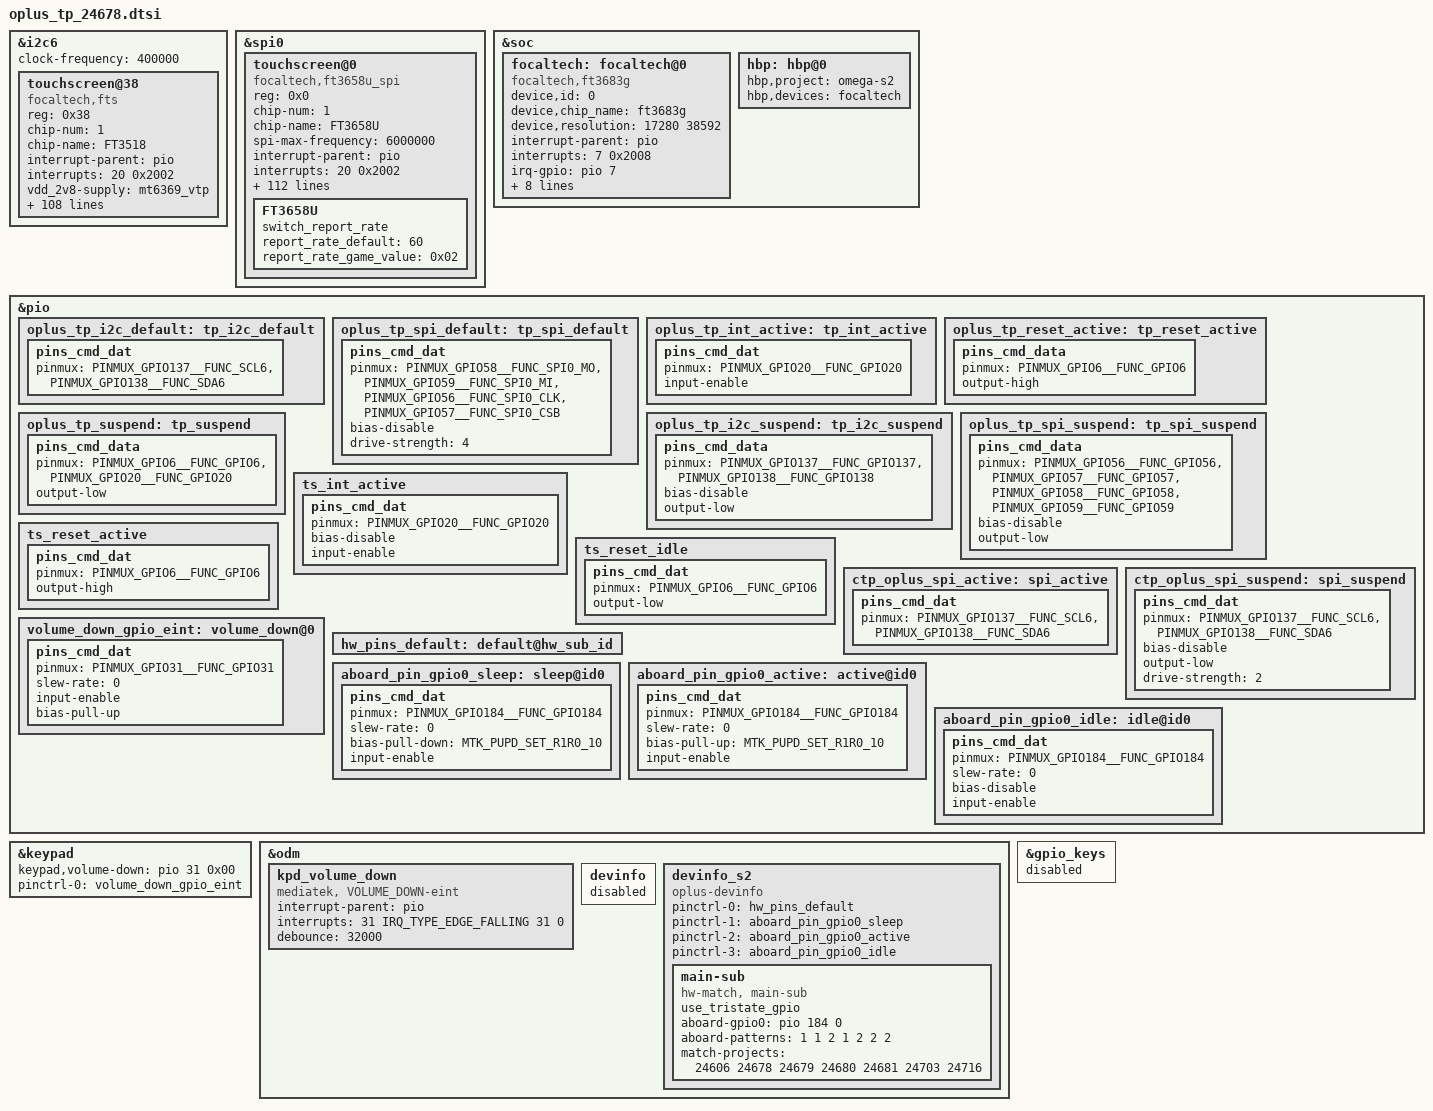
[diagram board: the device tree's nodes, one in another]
&i2c6 {
	status = "okay";
	#address-cells = <1>;
	#size-cells = <0>;
        clock-frequency = <400000>;
	touchscreen@38{
	    status = "okay";
		compatible = "focaltech,fts";
		reg = <0x38>;
		chip-num = <1>;
		chip-name = "FT3518";

		//spi-max-frequency = <12000000>;
		/* Interrupt && Irq-gpio */
		interrupt-parent = <&pio>;
		interrupts = <20 0x2002>;

		/* Power Config */
		vdd_2v8-supply  = <&mt6369_vtp>;
		vdd_2v8_volt = <3000000>;
		enable1v8_gpio = <&pio 22 0x1>;
		//vcc_1v8-supply  = <&mt6369_vtp>;
		//vcc_1v8_volt = <1800000>;


		/* Other HW Resource */

		irq-gpio = <&pio 20 0x2002>;
		reset-gpio = <&pio 6 0x1>;
		i2c_spi_switch = <&pio 41 0x1>;

		pinctrl-names = "default",  "sleep";
		pinctrl-0 = <&oplus_tp_int_active &oplus_tp_reset_active &oplus_tp_i2c_default>;
		pinctrl-1 = <&oplus_tp_suspend &oplus_tp_i2c_suspend>;

		touchpanel,max-num-support = <10>;
		touchpanel,tx-rx-num = <16 34>;
		touchpanel,panel-coords = <8640 19200>;
		touchpanel,display-coords = <1080 2400>;
		touchpanel,touchmajor-limit = <0 54>;
		touchpanel,smooth-level = <255 15 40 80 160 240>;
		touchpanel,sensitive-level = <255 30 25 20 10 8>;
		touchpanel,high-frame-rate-time = <20>;
		touchpanel,single-optimized-time = <8>;

		panel_type = <8>;
		firmware_name = "A865FT1";
		platform_support_project = <24606 24678 24679 24680 24681 24703 24716>;
		platform_support_project_dir = <24679 24679 24679 24679 24679 24679 24679>;
		platform_support_project_commandline = "default_commandline","default_commandline";

		prevention,curved_screen_V2;
		prevention,grip_disable_level = <6>;
		prevention,updelay_time_ms = <30>;
		prevention,makeup_cnt_weight = <4 1 2 2 2>;
		prevention,large_corner_range = <960 2400>;
		prevention,large_corner_judge_condition = <500 300 800 7 7>;
		prevention,trx_reject_condition = <9 6 7>;
		prevention,trx_strict_reject_condition = <8 5 6>;
		prevention,large_judge_time_ms = <500 50 30>;
		prevention,large_exit_condition = <8 8 2>;
		prevention,single_channel_width = <160 160>;
		prevention,normal_tap_condition = <10 350>;
		prevention,long_edge_condition = <200 80 180 80>;
		prevention,long_strict_edge_condition = <160 60>;
		prevention,long_fingerhold_condition = <50 6 4 4>;
		prevention,short_edge_condition = <200 80 180 80>;
		prevention,short_strict_edge_condition = <160 60>;
		prevention,large_strict_exit_condition = <4 4>;
		prevention,top_corner_config = <440 1200 360>;
		prevention,edge_swipe_config = <240 960>;

		prevention,curved_screen_V4;
		prevention,long_eliminate_point_type = <2 8640 6400 240 19200 300 1>;
		prevention,long_fingerhold_condition2 = <420 0 0 0>;
		prevention,top_corner_config2 = <3 80 480 0 0>;
		prevention,hor_long_top_corner_config = <240 1600 0 0>;
		prevention,top_middle_config = <8640 800 800 0>;
		prevention,corner_eliminate_point_type = <0 960 1600 1>;
		prevention,finger_hold_differ_size = <1 0 240 300>;
		prevention,finger_hold_max_rx_exit_distance = <5 240 1600>;
		prevention,max_rx_exit_distance = <1 5 150 240 1600>;
		prevention,dynamic_finger_hold_exit_distance = <1 240 1600 360>;
		prevention,edge_sliding_matched_support = <1 150 3 0>;
		//grip v4.2 reclining mode
		prevention,reclining_mode_support = <1>;
		prevention,long_eliminate_point_type_recli = <2 8640 6400 240 19200 500 0>;
		prevention,finger_hold_differ_size_recli = <1 0 240 400>;
		prevention,finger_hold_max_rx_exit_distance_recli = <4 240 1600>;
		prevention,max_rx_exit_distance_recli = <1 4 100 240 1600>;
		prevention,dynamic_finger_hold_exit_distance_recli = <1 240 1600 360>;
		prevention,edge_sliding_matched_support_recli = <1 200 3 0>;
		prevention,long_edge_condition_recli = <160 80 120 80>;

		/* SW Support Feature Control */
		black_gesture_support;
		black_gesture_indep_support;
		sportify_aod_gesture_support;
		pressure_report_support;
		charger_pump_support;
		game_switch_support;
		smart_gesture_support;
		fw_update_app_support;
		fingerprint_underscreen_support;
		screenoff_fingerprint_info_support;
		irq_need_dev_resume_ok;
		kernel_grip_support;
		//fw_edge_limit_support;
		exception_upload_support;
		health_monitor_support;
		//focalt x8 resolution config
		high_resolution_support;
		high_resolution_support_x8;
		disable_suspend_irq_handler_support;
		palm_to_sleep_support;
		snr_read_support;
		i2c_spi_compatible_support;
		esd_handle_support;
		diaphragm_touch_support;
		report_rate_white_list_support;
		/*
			*Virtual Key Config:
			*1:touchpanel,button-type: <virtualkey_type  supportted_button-map>
			*virtualkey_type:
			*Type 1: using board_properties
			*Type 2: using same IC (button zone&& touch zone are seprate)
			*Type 3: using diffrent IC (button zone&& touch zone are seprate)
			*Type 4: No need of virtual key process
			*supportted_button-map:select|menu|home|back
			*
			*2:touchpanel,button-map
			*type (X1,Y1)(X2,Y2)(X3,Y3)(Width_X,Hight_Y)--Only when button-type is 0
		*/
		touchpanel,button-type = <4>;
		touchpanel.button-TRx = <0 0>;

	};
};
&spi0 {
	status = "okay";
	#address-cells = <1>;
	#size-cells = <0>;
	touchscreen@0{
		compatible = "focaltech,ft3658u_spi";
		reg = <0x0>;
		chip-num = <1>;
		chip-name = "FT3658U";
		status = "okay";
		spi-max-frequency = <6000000>;
		/* Interrupt && Irq-gpio */
		interrupt-parent = <&pio>;
		interrupts = <20 0x2002>;

		/* Power Config */
		vdd_2v8-supply  = <&mt6369_vtp>;
		vdd_2v8_volt = <3000000>;
		enable1v8_gpio = <&pio 22 0x1>;
		//vcc_1v8-supply  = <&mt6369_vtp>;
		//vcc_1v8_volt = <1800000>;


		/* Other HW Resource */

		irq-gpio = <&pio 20 0x2002>;
		reset-gpio = <&pio 6 0x1>;
		i2c_spi_switch = <&pio 41 0x1>;

		pinctrl-names = "default",  "sleep";
		pinctrl-0 = <&oplus_tp_int_active &oplus_tp_reset_active &oplus_tp_spi_default>;
		pinctrl-1 = <&oplus_tp_suspend &oplus_tp_spi_suspend>;

		project_id = <24679>;
		touchpanel,max-num-support = <10>;
		touchpanel,tx-rx-num = <16 34>;
		touchpanel,panel-coords = <8640 19200>;
		touchpanel,display-coords = <1080 2400>;
		touchpanel,touchmajor-limit = <0 54>;
		touchpanel,smooth-level = <255 15 40 80 160 240>;
		touchpanel,sensitive-level = <255 30 25 20 10 8>;
		touchpanel,high-frame-rate-time = <20>;
		touchpanel,single-optimized-time = <8>;

		tp_type = <8 8>;
		firmware_name = "A865FT2";
		panel_type = <8>;
		platform_support_project = <24606 24678 24679 24680 24681 24703 24716>;
		platform_support_project_dir = <24679 24679 24679 24679 24679 24716 24716>;
		platform_support_project_commandline = "s6e8fc3_fhdp_dsi_vdo_samsung_ams667fk03_lcm_drv";

		prevention,curved_screen_V2;
		prevention,grip_disable_level = <6>;
		prevention,updelay_time_ms = <30>;
		prevention,makeup_cnt_weight = <4 1 2 2 2>;
		prevention,large_corner_range = <960 2400>;
		prevention,large_corner_judge_condition = <500 300 800 7 7>;
		prevention,trx_reject_condition = <9 6 7>;
		prevention,trx_strict_reject_condition = <8 5 6>;
		prevention,large_judge_time_ms = <500 50 30>;
		prevention,large_exit_condition = <8 8 2>;
		prevention,single_channel_width = <160 160>;
		prevention,normal_tap_condition = <10 350>;
		prevention,long_edge_condition = <200 80 180 80>;
		prevention,long_strict_edge_condition = <160 60>;
		prevention,long_fingerhold_condition = <50 6 4 4>;
		prevention,short_edge_condition = <200 80 180 80>;
		prevention,short_strict_edge_condition = <160 60>;
		prevention,large_strict_exit_condition = <4 4>;
		prevention,top_corner_config = <440 1200 360>;
		prevention,edge_swipe_config = <240 960>;

		prevention,curved_screen_V4;
		prevention,long_eliminate_point_type = <2 8640 6400 240 19200 300 1>;
		prevention,long_fingerhold_condition2 = <420 0 0 0>;
		prevention,top_corner_config2 = <3 80 480 0 0>;
		prevention,hor_long_top_corner_config = <240 1600 0 0>;
		prevention,top_middle_config = <8640 800 800 0>;
		prevention,corner_eliminate_point_type = <0 960 1600 1>;
		prevention,finger_hold_differ_size = <1 0 240 300>;
		prevention,finger_hold_max_rx_exit_distance = <5 240 1600>;
		prevention,max_rx_exit_distance = <1 5 150 240 1600>;
		prevention,dynamic_finger_hold_exit_distance = <1 240 1600 360>;
		prevention,edge_sliding_matched_support = <1 150 3 0>;
		//grip v4.2 reclining mode
		prevention,reclining_mode_support = <1>;
		prevention,long_eliminate_point_type_recli = <2 8640 6400 240 19200 500 0>;
		prevention,finger_hold_differ_size_recli = <1 0 240 400>;
		prevention,finger_hold_max_rx_exit_distance_recli = <4 240 1600>;
		prevention,max_rx_exit_distance_recli = <1 4 100 240 1600>;
		prevention,dynamic_finger_hold_exit_distance_recli = <1 240 1600 360>;
		prevention,edge_sliding_matched_support_recli = <1 200 3 0>;
		prevention,long_edge_condition_recli = <160 80 120 80>;

		/* SW Support Feature Control */
		black_gesture_support;
		black_gesture_indep_support;
		sportify_aod_gesture_support;
		pressure_report_support;
		charger_pump_support;
		game_switch_support;
		smart_gesture_support;
		fw_update_app_support;
		fingerprint_underscreen_support;
		screenoff_fingerprint_info_support;
		irq_need_dev_resume_ok;
		kernel_grip_support;
		//fw_edge_limit_support;
		exception_upload_support;
		health_monitor_support;
		//focalt x8 resolution config
		high_resolution_support;
		high_resolution_support_x8;
		disable_suspend_irq_handler_support;
		palm_to_sleep_support;
		snr_read_support;
		auto_test_force_pass_support;
		i2c_spi_compatible_support;
		esd_handle_support;
		diaphragm_touch_support;
		report_rate_white_list_support;
		/*
		*Virtual Key Config:
		*1:touchpanel,button-type: <virtualkey_type  supportted_button-map>
		*virtualkey_type:
		*Type 1: using board_properties
		*Type 2: using same IC (button zone&& touch zone are seprate)
		*Type 3: using diffrent IC (button zone&& touch zone are seprate)
		*Type 4: No need of virtual key process
		*supportted_button-map:select|menu|home|back
		*
		*2:touchpanel,button-map
		*type (X1,Y1)(X2,Y2)(X3,Y3)(Width_X,Hight_Y)--Only when button-type is 0
		*/
		touchpanel,button-type = <4>;
		touchpanel.button-TRx = <0 0>;

		FT3658U {
			switch_report_rate;
			report_rate_default = <60>;
			report_rate_game_value = <0x02>;
		};
	};
};
&soc {
	focaltech:focaltech@0 {
		compatible = "focaltech,ft3683g";
		status = "okay";

		device,id = <0>;
		device,chip_name = "ft3683g";
		device,resolution = <17280 38592>;

		/*interrupt config*/
		interrupt-parent = <&pio>;
		interrupts = <7 0x2008>;
		irq-gpio = <&pio 7 0x2002>;

		pinctrl-names = "default",
			"ts_reset_active",
			"ts_reset_idle",
			"ts_resume",
			"ts_suspend";
		pinctrl-0 = <&ts_int_active &ts_reset_active>;
		pinctrl-1 = <&ts_reset_active>;
		pinctrl-2 = <&ts_reset_idle>;
		pinctrl-3 = <&ctp_oplus_spi_active>;
		pinctrl-4 = <&ctp_oplus_spi_suspend>;

		/*cs active state, not used now*/
		spi,cs_active = <0>;

		/*power config*/
		// power,avdd-supply = <&wl28681c1_ldo6a>;
		// power,avdd_volt = <3204000 3204000>;
		power,vddi-supply = <&mt6369_vtp>;
		power,vddi_volt = <1800000 1800000>;

	};

	hbp:hbp@0 {
		//compatible = "oplus,hbp_core";
		hbp,project = "omega-s2";
		hbp,devices = <&focaltech>;
	};
};

&pio {
    oplus_tp_i2c_default: tp_i2c_default {
		pins_cmd_dat {
			pinmux =<PINMUX_GPIO137__FUNC_SCL6>,
					<PINMUX_GPIO138__FUNC_SDA6>;
		};
	};

    oplus_tp_spi_default: tp_spi_default {
		pins_cmd_dat {
		pinmux = <PINMUX_GPIO58__FUNC_SPI0_MO>,
				<PINMUX_GPIO59__FUNC_SPI0_MI>,
				<PINMUX_GPIO56__FUNC_SPI0_CLK>,
				<PINMUX_GPIO57__FUNC_SPI0_CSB>;
			bias-disable;
			drive-strength = <4>;
		};
	};

	oplus_tp_int_active: tp_int_active {
		pins_cmd_dat {
			pinmux = <PINMUX_GPIO20__FUNC_GPIO20>;
			input-enable;
		};
	};
	oplus_tp_reset_active: tp_reset_active {
		pins_cmd_data {
			pinmux = <PINMUX_GPIO6__FUNC_GPIO6>;
			output-high;
		};
	};
	oplus_tp_suspend: tp_suspend {
		pins_cmd_data {
			pinmux = <PINMUX_GPIO6__FUNC_GPIO6>,
					<PINMUX_GPIO20__FUNC_GPIO20>;
			output-low;
		};
	};

    oplus_tp_i2c_suspend: tp_i2c_suspend {
		pins_cmd_data {
			pinmux = <PINMUX_GPIO137__FUNC_GPIO137>,
			         <PINMUX_GPIO138__FUNC_GPIO138>;
			bias-disable;
			output-low;
		};
	};

	oplus_tp_spi_suspend: tp_spi_suspend {
		pins_cmd_data {
			pinmux = <PINMUX_GPIO56__FUNC_GPIO56>,
					<PINMUX_GPIO57__FUNC_GPIO57>,
					<PINMUX_GPIO58__FUNC_GPIO58>,
					<PINMUX_GPIO59__FUNC_GPIO59>;
			bias-disable;
			output-low;
		};
	};

	/*add for omega TP*/
	ts_int_active: ts_int_active {
		pins_cmd_dat {
			pinmux = <PINMUX_GPIO20__FUNC_GPIO20>;
			bias-disable;
			input-enable;
		};
	};
	ts_reset_active: ts_reset_active {
		pins_cmd_dat {
			pinmux = <PINMUX_GPIO6__FUNC_GPIO6>;
			output-high;
		};
	};
	ts_reset_idle: ts_reset_idle {
		pins_cmd_dat {
			pinmux = <PINMUX_GPIO6__FUNC_GPIO6>;
			output-low;
		};
	};
	ctp_oplus_spi_active: spi_active {
		pins_cmd_dat {
			pinmux = <PINMUX_GPIO137__FUNC_SCL6>,
					<PINMUX_GPIO138__FUNC_SDA6>;
		};
	};
	ctp_oplus_spi_suspend: spi_suspend {
		pins_cmd_dat {
			pinmux = <PINMUX_GPIO137__FUNC_SCL6>,
                     <PINMUX_GPIO138__FUNC_SDA6>;
			bias-disable;
			output-low;
			drive-strength = <2>;
		};
	};

};

&keypad {
		keypad,volume-down = <&pio 31 0x00>;
		pinctrl-names = "volume_down_as_int";
		pinctrl-0 = <&volume_down_gpio_eint>;
		status = "okay";
};

&pio {
        volume_down_gpio_eint:volume_down@0{
                pins_cmd_dat {
                        pinmux = <PINMUX_GPIO31__FUNC_GPIO31>;
                        slew-rate = <0>;  /*direction 0:in, 1:out*/
                        input-enable;
                        bias-pull-up;
                };
        };
};

&odm {
        kpd_volume_down:kpd_volume_down {
                compatible = "mediatek, VOLUME_DOWN-eint";
                interrupt-parent = <&pio>;
                interrupts = <31 IRQ_TYPE_EDGE_FALLING 31 0>;
                debounce = <32000>;
                status = "okay";
        };
};

&odm {
	devinfo {
		status = "disabled";
	};

	devinfo_s2 {
		compatible = "oplus-devinfo";

		pinctrl-names = "default", "aboard_gpio0_sleep", "aboard_gpio0_active", "aboard_gpio0_idle";
		pinctrl-0 = <&hw_pins_default>;
		pinctrl-1 = <&aboard_pin_gpio0_sleep>;
		pinctrl-2 = <&aboard_pin_gpio0_active>;
		pinctrl-3 = <&aboard_pin_gpio0_idle>;

		main-sub {
			compatible = "hw-match, main-sub";
			use_tristate_gpio;
			aboard-gpio0 = <&pio 184 0>;
			aboard-patterns = <1 1 2 1 2 2 2>;/*0[high-resistance] 1[pull-down] 2[pull-up]*/
			/*main board*/
			match-projects = <24606 24678 24679 24680 24681 24703 24716>;
		};
	};
};

&pio{
	hw_pins_default:default@hw_sub_id {
	};

	aboard_pin_gpio0_sleep:sleep@id0 {
		pins_cmd_dat {
			pinmux = <PINMUX_GPIO184__FUNC_GPIO184>;
			slew-rate = <0>;
			bias-pull-down = <MTK_PUPD_SET_R1R0_10>;
			input-enable;
		};
	};

	aboard_pin_gpio0_active:active@id0 {
		pins_cmd_dat {
			pinmux = <PINMUX_GPIO184__FUNC_GPIO184>;
			slew-rate = <0>;
			bias-pull-up = <MTK_PUPD_SET_R1R0_10>;
			input-enable;
		};
	};

	aboard_pin_gpio0_idle:idle@id0 {
		pins_cmd_dat {
			pinmux = <PINMUX_GPIO184__FUNC_GPIO184>;
			slew-rate = <0>;
			bias-disable;
			input-enable;
		};
	};
};

&gpio_keys {
	status = "disabled";
};
